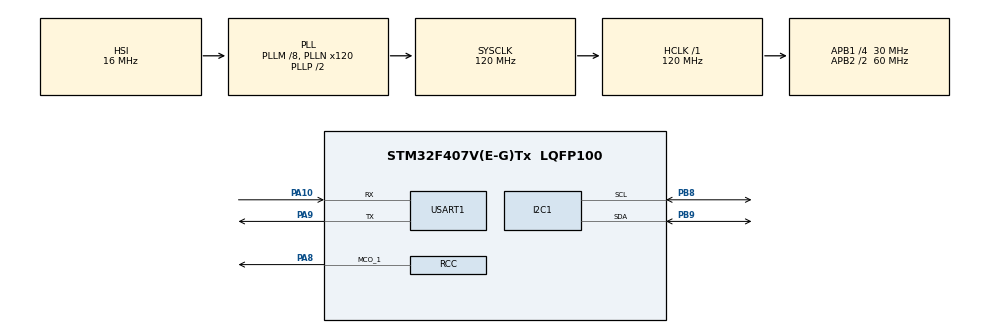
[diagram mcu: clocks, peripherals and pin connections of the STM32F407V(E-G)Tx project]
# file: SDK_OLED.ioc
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I2C1.I2C_Mode=I2C_Fast
Mcu.Family=STM32F4
Mcu.Name=STM32F407V(E-G)Tx
Mcu.Package=LQFP100
NVIC.PriorityGroup=NVIC_PRIORITYGROUP_4
PA10.Mode=Asynchronous
PA10.Signal=USART1_RX
PA13.Mode=JTAG_5_pins
PA13.Signal=SYS_JTMS-SWDIO
PA14.Mode=JTAG_5_pins
PA14.Signal=SYS_JTCK-SWCLK
PA15.Mode=JTAG_5_pins
PA15.Signal=SYS_JTDI
PA8.Mode=Clock-out-1
PA8.Signal=RCC_MCO_1
PA9.Mode=Asynchronous
PA9.Signal=USART1_TX
PB3.Mode=JTAG_5_pins
PB3.Signal=SYS_JTDO-SWO
PB4.Mode=JTAG_5_pins
PB4.Signal=SYS_JTRST
PB8.Mode=I2C
PB8.Signal=I2C1_SCL
PB9.Mode=I2C
PB9.Signal=I2C1_SDA
PH0-OSC_IN.Mode=HSE-External-Oscillator
PH0-OSC_IN.Signal=RCC_OSC_IN
PH1-OSC_OUT.Mode=HSE-External-Oscillator
PH1-OSC_OUT.Signal=RCC_OSC_OUT
ProjectManager.HeapSize=0x200
ProjectManager.StackSize=0x400
ProjectManager.TargetToolchain=SW4STM32
RCC.48MHZClocksFreq_Value=60000000
RCC.AHBFreq_Value=120000000
RCC.APB1CLKDivider=RCC_HCLK_DIV4
RCC.APB1Freq_Value=30000000
RCC.APB1TimFreq_Value=60000000
RCC.APB2CLKDivider=RCC_HCLK_DIV2
RCC.APB2Freq_Value=60000000
RCC.APB2TimFreq_Value=120000000
RCC.CortexFreq_Value=120000000
RCC.HCLKFreq_Value=120000000
RCC.HSE_VALUE=25000000
RCC.HSI_VALUE=16000000
RCC.LSE_VALUE=32768
RCC.PLLM=8
RCC.PLLN=120
RCC.SYSCLKFreq_VALUE=120000000
RCC.SYSCLKSource=RCC_SYSCLKSOURCE_PLLCLK
RCC.VCOOutputFreq_Value=240000000
USART1.VirtualMode=VM_ASYNC
board=custom

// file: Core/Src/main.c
/* USER CODE BEGIN Header */
/**
  ******************************************************************************
  * @file           : main.c
  * @brief          : Main program body
  ******************************************************************************
  ** This notice applies to any and all portions of this file
  * that are not between comment pairs USER CODE BEGIN and
  * USER CODE END. Other portions of this file, whether
  * inserted by the user or by software development tools
  * are owned by their respective copyright owners.
  *
  * COPYRIGHT(c) 2019 STMicroelectronics
  *
  * Redistribution and use in source and binary forms, with or without modification,
  * are permitted provided that the following conditions are met:
  *   1. Redistributions of source code must retain the above copyright notice,
  *      this list of conditions and the following disclaimer.
  *   2. Redistributions in binary form must reproduce the above copyright notice,
  *      this list of conditions and the following disclaimer in the documentation
  *      and/or other materials provided with the distribution.
  *   3. Neither the name of STMicroelectronics nor the names of its contributors
  *      may be used to endorse or promote products derived from this software
  *      without specific prior written permission.
  *
  * THIS SOFTWARE IS PROVIDED BY THE COPYRIGHT HOLDERS AND CONTRIBUTORS "AS IS"
  * AND ANY EXPRESS OR IMPLIED WARRANTIES, INCLUDING, BUT NOT LIMITED TO, THE
  * IMPLIED WARRANTIES OF MERCHANTABILITY AND FITNESS FOR A PARTICULAR PURPOSE ARE
  * DISCLAIMED. IN NO EVENT SHALL THE COPYRIGHT HOLDER OR CONTRIBUTORS BE LIABLE
  * FOR ANY DIRECT, INDIRECT, INCIDENTAL, SPECIAL, EXEMPLARY, OR CONSEQUENTIAL
  * DAMAGES (INCLUDING, BUT NOT LIMITED TO, PROCUREMENT OF SUBSTITUTE GOODS OR
  * SERVICES; LOSS OF USE, DATA, OR PROFITS; OR BUSINESS INTERRUPTION) HOWEVER
  * CAUSED AND ON ANY THEORY OF LIABILITY, WHETHER IN CONTRACT, STRICT LIABILITY,
  * OR TORT (INCLUDING NEGLIGENCE OR OTHERWISE) ARISING IN ANY WAY OUT OF THE USE
  * OF THIS SOFTWARE, EVEN IF ADVISED OF THE POSSIBILITY OF SUCH DAMAGE.
  *
  ******************************************************************************
  */
/* USER CODE END Header */

#include "main.h"
#include "i2c.h"
#include "usart.h"
#include "gpio.h"
#include "oled.h"
#include "fonts.h"

void SystemClock_Config(void);

int main(void)
{

  /* MCU Configuration--------------------------------------------------------*/

  /* Reset of all peripherals, Initializes the Flash interface and the Systick. */
  HAL_Init();

  /* Configure the system clock */
  SystemClock_Config();

  /* Initialize all configured peripherals */
  MX_GPIO_Init();
  MX_I2C1_Init();
  MX_USART1_UART_Init();
  /* USER CODE BEGIN 2 */
  oled_Init();
  /* USER CODE END 2 */

  /* Infinite loop */
  while (1)
  {
	  oled_SetCursor(0,0);
	  oled_WriteString("Hello World",Font_11x18,White);
	  oled_UpdateScreen();
	  HAL_Delay(2000);
	  oled_Fill(Black);
	  oled_SetCursor(0,0);
	  oled_WriteString("SDK-1.1M",Font_11x18,White);
	  oled_UpdateScreen();
	  HAL_Delay(2000);
  }
}

void SystemClock_Config(void)
{
  RCC_OscInitTypeDef RCC_OscInitStruct = {0};
  RCC_ClkInitTypeDef RCC_ClkInitStruct = {0};

  /**Configure the main internal regulator output voltage
  */
  __HAL_RCC_PWR_CLK_ENABLE();
  __HAL_PWR_VOLTAGESCALING_CONFIG(PWR_REGULATOR_VOLTAGE_SCALE1);
  /**Initializes the CPU, AHB and APB busses clocks
  */
  RCC_OscInitStruct.OscillatorType = RCC_OSCILLATORTYPE_HSI;
  RCC_OscInitStruct.HSIState = RCC_HSI_ON;
  RCC_OscInitStruct.HSICalibrationValue = RCC_HSICALIBRATION_DEFAULT;
  RCC_OscInitStruct.PLL.PLLState = RCC_PLL_ON;
  RCC_OscInitStruct.PLL.PLLSource = RCC_PLLSOURCE_HSI;
  RCC_OscInitStruct.PLL.PLLM = 8;
  RCC_OscInitStruct.PLL.PLLN = 120;
  RCC_OscInitStruct.PLL.PLLP = RCC_PLLP_DIV2;
  RCC_OscInitStruct.PLL.PLLQ = 4;
  if (HAL_RCC_OscConfig(&RCC_OscInitStruct) != HAL_OK)
  {
    Error_Handler();
  }
  /**Initializes the CPU, AHB and APB busses clocks
  */
  RCC_ClkInitStruct.ClockType = RCC_CLOCKTYPE_HCLK|RCC_CLOCKTYPE_SYSCLK
                              |RCC_CLOCKTYPE_PCLK1|RCC_CLOCKTYPE_PCLK2;
  RCC_ClkInitStruct.SYSCLKSource = RCC_SYSCLKSOURCE_PLLCLK;
  RCC_ClkInitStruct.AHBCLKDivider = RCC_SYSCLK_DIV1;
  RCC_ClkInitStruct.APB1CLKDivider = RCC_HCLK_DIV4;
  RCC_ClkInitStruct.APB2CLKDivider = RCC_HCLK_DIV2;

  if (HAL_RCC_ClockConfig(&RCC_ClkInitStruct, FLASH_LATENCY_3) != HAL_OK)
  {
    Error_Handler();
  }
  HAL_RCC_MCOConfig(RCC_MCO1, RCC_MCO1SOURCE_HSI, RCC_MCODIV_1);
}

void Error_Handler(void)
{
}

/************************ (C) COPYRIGHT STMicroelectronics *****END OF FILE****/
